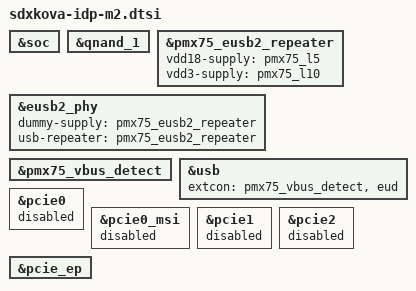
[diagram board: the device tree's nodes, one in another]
// SPDX-License-Identifier: BSD-3-Clause
/*
 * Copyright (c) 2024 Qualcomm Innovation Center, Inc. All rights reserved.
 */

#include "sdxkova-pmic-overlay.dtsi"

&soc {
};

&qnand_1 {
	status = "ok";
};

&pmx75_eusb2_repeater {
	vdd18-supply = <&pmx75_l5>;
	vdd3-supply = <&pmx75_l10>;
	status = "ok";
};

&eusb2_phy {
	dummy-supply = <&pmx75_eusb2_repeater>;
	usb-repeater = <&pmx75_eusb2_repeater>;
};

&pmx75_vbus_detect {
	status = "ok";
};

&usb {
	extcon = <&pmx75_vbus_detect>, <&eud>;
};

&pcie0 {
	status = "disabled";
};

&pcie0_msi {
	status = "disabled";
};

&pcie1 {
	status = "disabled";
};

&pcie2 {
	status = "disabled";
};

&pcie_ep {
	status = "ok";
};
